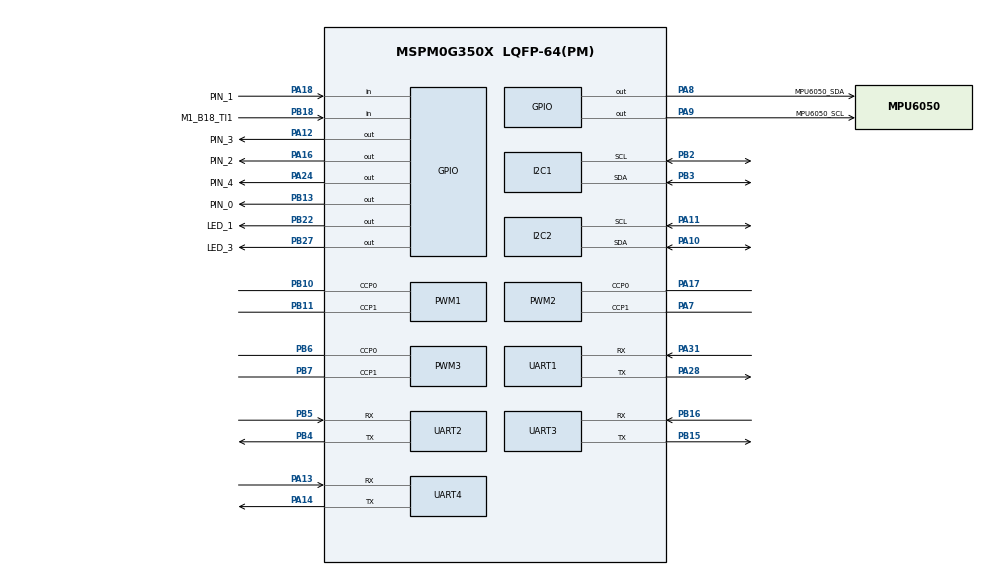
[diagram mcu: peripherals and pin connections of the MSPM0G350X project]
/**
 * @cliArgs --device "MSPM0G350X" --package "LQFP-64(PM)" --part "Default" --product "mspm0_sdk@2.01.00.03"
 * @versions {"tool":"1.20.0+3587"}
 */

/**
 * Import the modules used in this configuration.
 */
const ADC12  = scripting.addModule("/ti/driverlib/ADC12", {}, false);
const ADC121 = ADC12.addInstance();
const ADC122 = ADC12.addInstance();
const Board  = scripting.addModule("/ti/driverlib/Board");
const DMA    = scripting.addModule("/ti/driverlib/DMA");
const GPIO   = scripting.addModule("/ti/driverlib/GPIO", {}, false);
const GPIO1  = GPIO.addInstance();
const GPIO2  = GPIO.addInstance();
const GPIO3  = GPIO.addInstance();
const GPIO4  = GPIO.addInstance();
const GPIO5  = GPIO.addInstance();
const GPIO6  = GPIO.addInstance();
const GPIO7  = GPIO.addInstance();
const GPIO8  = GPIO.addInstance();
const I2C    = scripting.addModule("/ti/driverlib/I2C", {}, false);
const I2C1   = I2C.addInstance();
const I2C2   = I2C.addInstance();
const PWM    = scripting.addModule("/ti/driverlib/PWM", {}, false);
const PWM1   = PWM.addInstance();
const PWM2   = PWM.addInstance();
const PWM3   = PWM.addInstance();
const SYSCTL = scripting.addModule("/ti/driverlib/SYSCTL");
const TIMER  = scripting.addModule("/ti/driverlib/TIMER", {}, false);
const TIMER1 = TIMER.addInstance();
const TIMER2 = TIMER.addInstance();
const TIMER3 = TIMER.addInstance();
const UART   = scripting.addModule("/ti/driverlib/UART", {}, false);
const UART1  = UART.addInstance();
const UART2  = UART.addInstance();
const UART3  = UART.addInstance();
const UART4  = UART.addInstance();

/**
 * Write custom configuration values to the imported modules.
 */
const divider6       = system.clockTree["PLL_CLK2X_DIV"];
divider6.divideValue = 4;

const divider7       = system.clockTree["PLL_PDIV"];
divider7.divideValue = 2;

const divider9       = system.clockTree["UDIV"];
divider9.divideValue = 2;

const multiplier2         = system.clockTree["PLL_QDIV"];
multiplier2.multiplyValue = 10;

const mux8       = system.clockTree["HSCLKMUX"];
mux8.inputSelect = "HSCLKMUX_SYSPLL2X";

ADC121.$name                      = "ADC12_0";
ADC121.peripheral.adcPin0.$assign = "PA27";
ADC121.adcPin0Config.$name        = "ti_driverlib_gpio_GPIOPinGeneric16";

ADC122.$name                      = "ADC12_1";
ADC122.peripheral.adcPin0.$assign = "PA15";
ADC122.adcPin0Config.$name        = "ti_driverlib_gpio_GPIOPinGeneric17";


GPIO1.$name                          = "GPIO_LEDS";
GPIO1.associatedPins.create(3);
GPIO1.associatedPins[0].$name        = "LED_1";
GPIO1.associatedPins[0].assignedPort = "PORTB";
GPIO1.associatedPins[0].assignedPin  = "22";
GPIO1.associatedPins[0].pin.$assign  = "PB22";
GPIO1.associatedPins[1].$name        = "LED_2";
GPIO1.associatedPins[1].assignedPort = "PORTA";
GPIO1.associatedPins[1].assignedPin  = "26";
GPIO1.associatedPins[2].$name        = "LED_3";
GPIO1.associatedPins[2].assignedPort = "PORTB";
GPIO1.associatedPins[2].assignedPin  = "27";
GPIO1.associatedPins[2].pin.$assign  = "PB27";

GPIO2.$name                          = "GPIO_KEYS";
GPIO2.associatedPins.create(2);
GPIO2.associatedPins[0].$name        = "PIN_1";
GPIO2.associatedPins[0].direction    = "INPUT";
GPIO2.associatedPins[0].assignedPort = "PORTA";
GPIO2.associatedPins[0].assignedPin  = "18";
GPIO2.associatedPins[0].pin.$assign  = "PA18";
GPIO2.associatedPins[1].$name        = "PIN_5";
GPIO2.associatedPins[1].direction    = "INPUT";
GPIO2.associatedPins[1].assignedPin  = "21";
GPIO2.associatedPins[1].assignedPort = "PORTB";

GPIO3.$name                          = "GPIO_Encoders";
GPIO3.associatedPins.create(4);
GPIO3.associatedPins[0].$name        = "M2_B0_TI1";
GPIO3.associatedPins[0].direction    = "INPUT";
GPIO3.associatedPins[0].assignedPort = "PORTB";
GPIO3.associatedPins[0].assignedPin  = "0";
GPIO3.associatedPins[0].interruptEn  = true;
GPIO3.associatedPins[0].polarity     = "RISE";
GPIO3.associatedPins[1].$name        = "M2_B1_TI2";
GPIO3.associatedPins[1].direction    = "INPUT";
GPIO3.associatedPins[1].assignedPort = "PORTB";
GPIO3.associatedPins[1].assignedPin  = "1";
GPIO3.associatedPins[2].direction    = "INPUT";
GPIO3.associatedPins[2].assignedPort = "PORTB";
GPIO3.associatedPins[2].assignedPin  = "18";
GPIO3.associatedPins[2].$name        = "M1_B18_TI1";
GPIO3.associatedPins[2].interruptEn  = true;
GPIO3.associatedPins[2].polarity     = "RISE";
GPIO3.associatedPins[2].pin.$assign  = "PB18";
GPIO3.associatedPins[3].direction    = "INPUT";
GPIO3.associatedPins[3].assignedPort = "PORTB";
GPIO3.associatedPins[3].$name        = "M1_B17_TI2";
GPIO3.associatedPins[3].assignedPin  = "17";

GPIO4.$name                          = "MPU6050";
GPIO4.associatedPins.create(2);
GPIO4.associatedPins[0].$name        = "MPU6050_SDA";
GPIO4.associatedPins[0].assignedPort = "PORTA";
GPIO4.associatedPins[0].assignedPin  = "8";
GPIO4.associatedPins[0].pin.$assign  = "PA8";
GPIO4.associatedPins[1].$name        = "MPU6050_SCL";
GPIO4.associatedPins[1].assignedPort = "PORTA";
GPIO4.associatedPins[1].assignedPin  = "9";
GPIO4.associatedPins[1].pin.$assign  = "PA9";

GPIO5.$name                         = "TB6612A0";
GPIO5.associatedPins[0].$name       = "PIN_0";
GPIO5.associatedPins[0].pin.$assign = "PB13";

GPIO6.$name                         = "TB6612A1";
GPIO6.associatedPins[0].$name       = "PIN_2";
GPIO6.associatedPins[0].pin.$assign = "PA16";

GPIO7.$name                         = "TB6612B0";
GPIO7.associatedPins[0].$name       = "PIN_3";
GPIO7.associatedPins[0].pin.$assign = "PA12";

GPIO8.$name                         = "TB6612B1";
GPIO8.associatedPins[0].$name       = "PIN_4";
GPIO8.associatedPins[0].pin.$assign = "PA24";

I2C1.basicEnableController             = true;
I2C1.$name                             = "I2C_MPU6050";
I2C1.intController                     = ["ARBITRATION_LOST","NACK","RXFIFO_TRIGGER","RX_DONE","TX_DONE"];
I2C1.peripheral.$assign                = "I2C1";
I2C1.peripheral.sdaPin.$assign         = "PB3";
I2C1.peripheral.sclPin.$assign         = "PB2";
I2C1.sdaPinConfig.hideOutputInversion  = scripting.forceWrite(false);
I2C1.sdaPinConfig.onlyInternalResistor = scripting.forceWrite(false);
I2C1.sdaPinConfig.passedPeripheralType = scripting.forceWrite("Digital");
I2C1.sdaPinConfig.$name                = "ti_driverlib_gpio_GPIOPinGeneric0";
I2C1.sclPinConfig.hideOutputInversion  = scripting.forceWrite(false);
I2C1.sclPinConfig.onlyInternalResistor = scripting.forceWrite(false);
I2C1.sclPinConfig.passedPeripheralType = scripting.forceWrite("Digital");
I2C1.sclPinConfig.$name                = "ti_driverlib_gpio_GPIOPinGeneric1";

I2C2.$name                             = "I2C_0";
I2C2.basicEnableController             = true;
I2C2.peripheral.$assign                = "I2C0";
I2C2.peripheral.sdaPin.$assign         = "PA10";
I2C2.peripheral.sclPin.$assign         = "PA11";
I2C2.sdaPinConfig.hideOutputInversion  = scripting.forceWrite(false);
I2C2.sdaPinConfig.onlyInternalResistor = scripting.forceWrite(false);
I2C2.sdaPinConfig.passedPeripheralType = scripting.forceWrite("Digital");
I2C2.sdaPinConfig.$name                = "ti_driverlib_gpio_GPIOPinGeneric14";
I2C2.sclPinConfig.hideOutputInversion  = scripting.forceWrite(false);
I2C2.sclPinConfig.onlyInternalResistor = scripting.forceWrite(false);
I2C2.sclPinConfig.passedPeripheralType = scripting.forceWrite("Digital");
I2C2.sclPinConfig.$name                = "ti_driverlib_gpio_GPIOPinGeneric15";

PWM1.$name                      = "PWM_0";
PWM1.timerStartTimer            = true;
PWM1.clockPrescale              = 79;
PWM1.timerCount                 = 10000;
PWM1.pwmMode                    = "EDGE_ALIGN_UP";
PWM1.peripheral.$assign         = "TIMG8";
PWM1.peripheral.ccp0Pin.$assign = "PB10";
PWM1.peripheral.ccp1Pin.$assign = "PB11";
PWM1.PWM_CHANNEL_0.$name        = "ti_driverlib_pwm_PWMTimerCC0";
PWM1.PWM_CHANNEL_1.$name        = "ti_driverlib_pwm_PWMTimerCC1";
PWM1.ccp0PinConfig.$name        = "ti_driverlib_gpio_GPIOPinGeneric10";
PWM1.ccp1PinConfig.$name        = "ti_driverlib_gpio_GPIOPinGeneric11";

PWM2.$name                      = "PWM_1";
PWM2.timerStartTimer            = true;
PWM2.clockPrescale              = 79;
PWM2.timerCount                 = 10000;
PWM2.peripheral.ccp0Pin.$assign = "PA17";
PWM2.peripheral.ccp1Pin.$assign = "PA7";
PWM2.PWM_CHANNEL_0.$name        = "ti_driverlib_pwm_PWMTimerCC2";
PWM2.PWM_CHANNEL_1.$name        = "ti_driverlib_pwm_PWMTimerCC3";
PWM2.ccp0PinConfig.$name        = "ti_driverlib_gpio_GPIOPinGeneric12";
PWM2.ccp1PinConfig.$name        = "ti_driverlib_gpio_GPIOPinGeneric13";

PWM3.$name                      = "PWM_2";
PWM3.clockPrescale              = 79;
PWM3.timerCount                 = 5000;
PWM3.peripheral.ccp0Pin.$assign = "PB6";
PWM3.peripheral.ccp1Pin.$assign = "PB7";
PWM3.PWM_CHANNEL_0.$name        = "ti_driverlib_pwm_PWMTimerCC4";
PWM3.PWM_CHANNEL_1.$name        = "ti_driverlib_pwm_PWMTimerCC5";
PWM3.ccp0PinConfig.$name        = "ti_driverlib_gpio_GPIOPinGeneric18";
PWM3.ccp1PinConfig.$name        = "ti_driverlib_gpio_GPIOPinGeneric19";

SYSCTL.forceDefaultClkConfig = true;

TIMER1.$name              = "TIMER_0";
TIMER1.timerClkPrescale   = 256;
TIMER1.timerMode          = "PERIODIC";
TIMER1.interrupts         = ["ZERO"];
TIMER1.timerClkDiv        = 2;
TIMER1.timerPeriod        = "0.1s";
TIMER1.peripheral.$assign = "TIMA1";

TIMER2.$name              = "TIMER_1";
TIMER2.timerClkDiv        = 2;
TIMER2.timerClkPrescale   = 256;
TIMER2.timerMode          = "PERIODIC";
TIMER2.interrupts         = ["ZERO"];
TIMER2.timerPeriod        = "0.05";
TIMER2.peripheral.$assign = "TIMG0";

TIMER3.$name              = "TIMER_2";
TIMER3.timerClkDiv        = 2;
TIMER3.timerClkPrescale   = 256;
TIMER3.timerMode          = "PERIODIC";
TIMER3.interrupts         = ["ZERO"];
TIMER3.timerPeriod        = "5 ms";
TIMER3.peripheral.$assign = "TIMA0";

UART1.$name                    = "UART_0";
UART1.targetBaudRate           = 115200;
UART1.enabledInterrupts        = ["RX"];
UART1.peripheral.$assign       = "UART0";
UART1.peripheral.rxPin.$assign = "PA31";
UART1.peripheral.txPin.$assign = "PA28";
UART1.txPinConfig.$name        = "ti_driverlib_gpio_GPIOPinGeneric2";
UART1.rxPinConfig.$name        = "ti_driverlib_gpio_GPIOPinGeneric3";

UART2.$name                    = "UART_1";
UART2.targetBaudRate           = 115200;
UART2.enabledInterrupts        = ["RX"];
UART2.peripheral.$assign       = "UART1";
UART2.peripheral.rxPin.$assign = "PB5";
UART2.peripheral.txPin.$assign = "PB4";
UART2.txPinConfig.$name        = "ti_driverlib_gpio_GPIOPinGeneric4";
UART2.rxPinConfig.$name        = "ti_driverlib_gpio_GPIOPinGeneric5";

UART3.$name                    = "UART_2";
UART3.targetBaudRate           = 115200;
UART3.enabledInterrupts        = ["RX"];
UART3.peripheral.$assign       = "UART2";
UART3.peripheral.rxPin.$assign = "PB16";
UART3.peripheral.txPin.$assign = "PB15";
UART3.txPinConfig.$name        = "ti_driverlib_gpio_GPIOPinGeneric6";
UART3.rxPinConfig.$name        = "ti_driverlib_gpio_GPIOPinGeneric7";

UART4.$name                    = "UART_3";
UART4.targetBaudRate           = 115200;
UART4.enabledInterrupts        = ["RX"];
UART4.enableDMARX              = false;
UART4.peripheral.rxPin.$assign = "PA13";
UART4.peripheral.txPin.$assign = "PA14";
UART4.txPinConfig.$name        = "ti_driverlib_gpio_GPIOPinGeneric8";
UART4.rxPinConfig.$name        = "ti_driverlib_gpio_GPIOPinGeneric9";

/**
 * Pinmux solution for unlocked pins/peripherals. This ensures that minor changes to the automatic solver in a future
 * version of the tool will not impact the pinmux you originally saw.  These lines can be completely deleted in order to
 * re-solve from scratch.
 */
ADC121.peripheral.$suggestSolution           = "ADC0";
ADC122.peripheral.$suggestSolution           = "ADC1";
Board.peripheral.$suggestSolution            = "DEBUGSS";
Board.peripheral.swclkPin.$suggestSolution   = "PA20";
Board.peripheral.swdioPin.$suggestSolution   = "PA19";
GPIO1.associatedPins[1].pin.$suggestSolution = "PA26";
GPIO2.associatedPins[1].pin.$suggestSolution = "PB21";
GPIO3.associatedPins[0].pin.$suggestSolution = "PB0";
GPIO3.associatedPins[1].pin.$suggestSolution = "PB1";
GPIO3.associatedPins[3].pin.$suggestSolution = "PB17";
PWM2.peripheral.$suggestSolution             = "TIMG7";
PWM3.peripheral.$suggestSolution             = "TIMG6";
SYSCTL.peripheral.$suggestSolution           = "SYSCTL";
UART4.peripheral.$suggestSolution            = "UART3";
